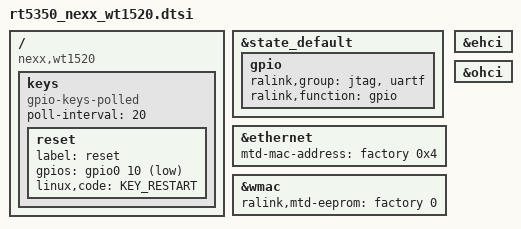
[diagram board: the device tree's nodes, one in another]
#include "rt5350.dtsi"

#include <dt-bindings/gpio/gpio.h>
#include <dt-bindings/input/input.h>

/ {
	compatible = "nexx,wt1520", "ralink,rt5350-soc";

	keys {
		compatible = "gpio-keys-polled";
		poll-interval = <20>;

		reset {
			label = "reset";
			gpios = <&gpio0 10 GPIO_ACTIVE_LOW>;
			linux,code = <KEY_RESTART>;
		};
	};
};

&state_default {
	gpio {
		ralink,group = "jtag", "uartf";
		ralink,function = "gpio";
	};
};

&ethernet {
	mtd-mac-address = <&factory 0x4>;
};

&wmac {
	ralink,mtd-eeprom = <&factory 0>;
};

&ehci {
	status = "okay";
};

&ohci {
	status = "okay";
};
